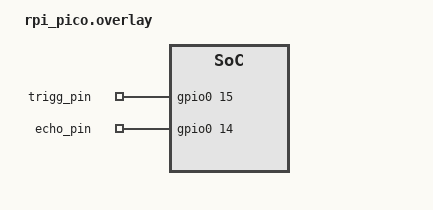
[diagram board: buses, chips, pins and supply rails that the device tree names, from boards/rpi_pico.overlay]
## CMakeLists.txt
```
cmake_minimum_required(VERSION 3.20.0)

find_package(Zephyr REQUIRED HINTS $ENV{ZEPHYR_BASE})

project(RTOS)

target_sources(app PRIVATE src/main.c)
```

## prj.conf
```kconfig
CONFIG_GPIO=y
CONFIG_ADC=y
CONFIG_SERIAL=y
CONFIG_PRINTK=y

CONFIG_USB_DEVICE_STACK_NEXT=y
CONFIG_CDC_ACM_SERIAL_INITIALIZE_AT_BOOT=y

CONFIG_CBPRINTF_FP_SUPPORT=y
```

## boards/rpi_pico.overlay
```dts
/{
    ultrasonic_trig{
        compatible = "gpio-leds";
        trigg_pin: pin15{
            gpios = <&gpio0 15 GPIO_ACTIVE_HIGH>;
        };
    };
    ultrasonic_echo{
        compatible = "gpio-keys";
        echo_pin: pin14{
            gpios = <&gpio0 14 GPIO_ACTIVE_HIGH>;
        };
    };
    aliases{
        trigg = &trigg_pin;
        echo = &echo_pin;
    };
};
```

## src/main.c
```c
#include <zephyr/kernel.h>
#include <zephyr/devicetree.h>
#include <zephyr/drivers/gpio.h>

#define TRIGG DT_ALIAS(trigg)
#define ECHO DT_ALIAS(echo)

static const struct gpio_dt_spec trigg_pin = GPIO_DT_SPEC_GET(TRIGG, gpios);
static const struct gpio_dt_spec echo_pin  = GPIO_DT_SPEC_GET(ECHO, gpios);

int main(){

    int count;
    float distance;

    gpio_pin_configure_dt(&trigg_pin, GPIO_OUTPUT);
    gpio_pin_configure_dt(&echo_pin, GPIO_INPUT);

    while(1)
    {
        count = 0;

        gpio_pin_set_dt(&trigg_pin, 1);
        k_busy_wait(10); //10uS delay
        gpio_pin_set_dt(&trigg_pin, 0);

        while(gpio_pin_get_dt(&echo_pin) == 0);

        while(gpio_pin_get_dt(&echo_pin) == 1)
        {
            k_busy_wait(10);
            count ++;
        }

        distance = (count * 10.0f) / 58.0f;

        printk("Distance: %.2f cm\n", (double)distance);

        k_msleep(100);

    }

    return 0;
}
```
